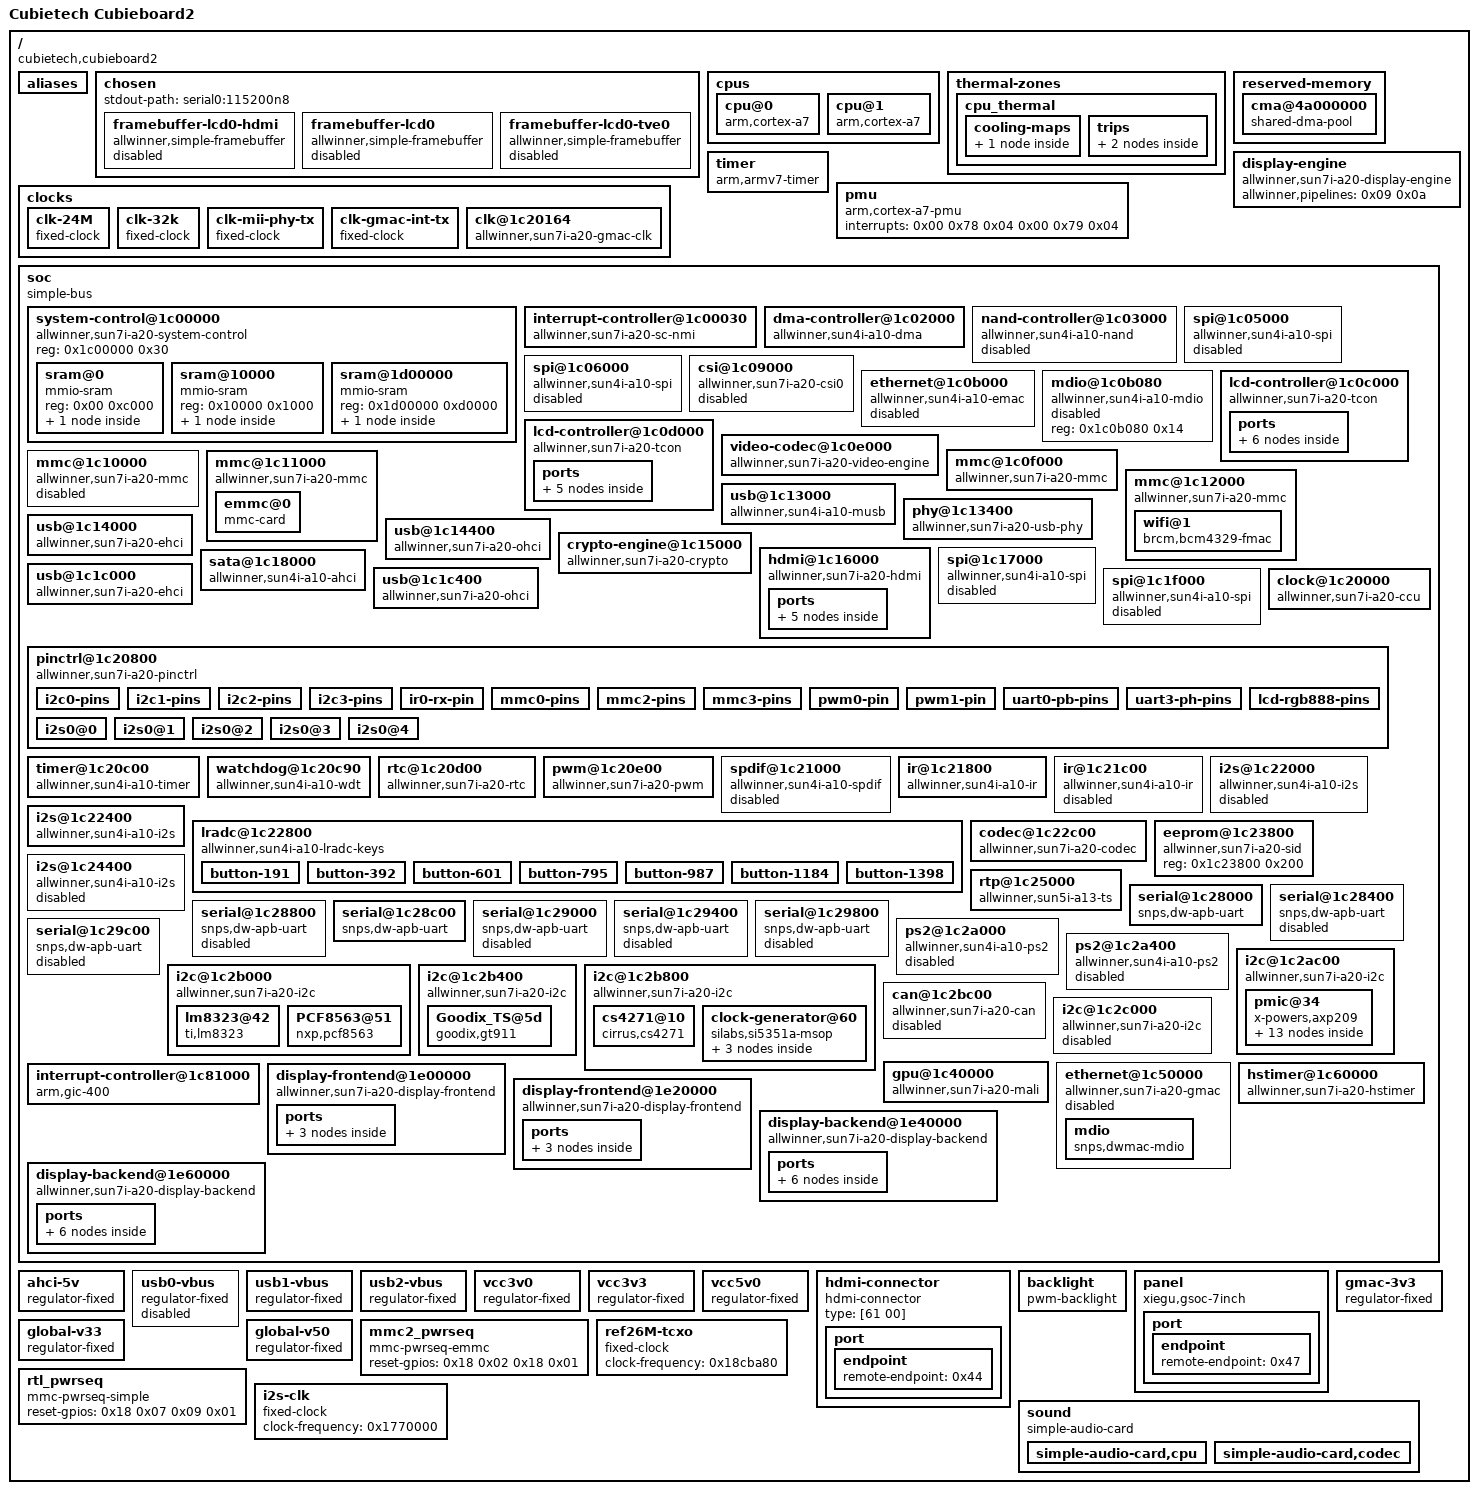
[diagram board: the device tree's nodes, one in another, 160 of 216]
/dts-v1/;

/ {
	interrupt-parent = <0x01>;
	#address-cells = <0x01>;
	#size-cells = <0x01>;
	model = "Cubietech Cubieboard2";
	compatible = "cubietech,cubieboard2\0allwinner,sun7i-a20";

	aliases {
		ethernet0 = "/soc/ethernet@1c50000";
		serial0 = "/soc/serial@1c28000";
	};

	chosen {
		#address-cells = <0x01>;
		#size-cells = <0x01>;
		ranges;
		stdout-path = "serial0:115200n8";

		framebuffer-lcd0-hdmi {
			compatible = "allwinner,simple-framebuffer\0simple-framebuffer";
			allwinner,pipeline = "de_be0-lcd0-hdmi";
			clocks = <0x02 0x38 0x02 0x3c 0x02 0x3e 0x02 0x90 0x02 0x9b 0x02 0x8c 0x02 0xa4>;
			status = "disabled";
		};

		framebuffer-lcd0 {
			compatible = "allwinner,simple-framebuffer\0simple-framebuffer";
			allwinner,pipeline = "de_be0-lcd0";
			clocks = <0x02 0x38 0x02 0x3e 0x02 0x90 0x02 0x95 0x02 0x8c>;
			status = "disabled";
		};

		framebuffer-lcd0-tve0 {
			compatible = "allwinner,simple-framebuffer\0simple-framebuffer";
			allwinner,pipeline = "de_be0-lcd0-tve0";
			clocks = <0x02 0x36 0x02 0x38 0x02 0x3e 0x02 0x90 0x02 0x9b 0x02 0x87 0x02 0x8c>;
			status = "disabled";
		};
	};

	cpus {
		#address-cells = <0x01>;
		#size-cells = <0x00>;

		cpu@0 {
			compatible = "arm,cortex-a7";
			device_type = "cpu";
			reg = <0x00>;
			clocks = <0x02 0x14>;
			clock-latency = <0x3b9b0>;
			operating-points = <0xea600 0x155cc0 0xdea80 0x155cc0 0xd2f00 0x13d620 0xafc80 0x124f80 0x80e80 0x10c8e0 0x4c2c0 0xf4240 0x23280 0xf4240>;
			#cooling-cells = <0x02>;
			phandle = <0x05>;
		};

		cpu@1 {
			compatible = "arm,cortex-a7";
			device_type = "cpu";
			reg = <0x01>;
			clocks = <0x02 0x14>;
			clock-latency = <0x3b9b0>;
			operating-points = <0xea600 0x155cc0 0xdea80 0x155cc0 0xd2f00 0x13d620 0xafc80 0x124f80 0x80e80 0x10c8e0 0x4c2c0 0xf4240 0x23280 0xf4240>;
			#cooling-cells = <0x02>;
			phandle = <0x06>;
		};
	};

	thermal-zones {

		cpu_thermal {
			polling-delay-passive = <0xfa>;
			polling-delay = <0x3e8>;
			thermal-sensors = <0x03>;

			cooling-maps {

				map0 {
					trip = <0x04>;
					cooling-device = <0x05 0xffffffff 0xffffffff 0x06 0xffffffff 0xffffffff>;
				};
			};

			trips {

				cpu_alert0 {
					temperature = <0x124f8>;
					hysteresis = <0x7d0>;
					type = "passive";
					phandle = <0x04>;
				};

				cpu_crit {
					temperature = <0x186a0>;
					hysteresis = <0x7d0>;
					type = "critical";
				};
			};
		};
	};

	reserved-memory {
		#address-cells = <0x01>;
		#size-cells = <0x01>;
		ranges;

		cma@4a000000 {
			compatible = "shared-dma-pool";
			size = <0x8000000>;
			alloc-ranges = <0x4a000000 0x8000000>;
			reusable;
			linux,cma-default;
			phandle = <0x36>;
		};
	};

	timer {
		compatible = "arm,armv7-timer";
		interrupts = <0x01 0x0d 0xf08 0x01 0x0e 0xf08 0x01 0x0b 0xf08 0x01 0x0a 0xf08>;
	};

	pmu {
		compatible = "arm,cortex-a7-pmu";
		interrupts = <0x00 0x78 0x04 0x00 0x79 0x04>;
	};

	clocks {
		#address-cells = <0x01>;
		#size-cells = <0x01>;
		ranges;

		clk-24M {
			#clock-cells = <0x00>;
			compatible = "fixed-clock";
			clock-frequency = <0x16e3600>;
			clock-output-names = "osc24M";
			phandle = <0x23>;
		};

		clk-32k {
			#clock-cells = <0x00>;
			compatible = "fixed-clock";
			clock-frequency = <0x8000>;
			clock-output-names = "osc32k";
			phandle = <0x24>;
		};

		clk-mii-phy-tx {
			#clock-cells = <0x00>;
			compatible = "fixed-clock";
			clock-frequency = <0x17d7840>;
			clock-output-names = "mii_phy_tx";
			phandle = <0x07>;
		};

		clk-gmac-int-tx {
			#clock-cells = <0x00>;
			compatible = "fixed-clock";
			clock-frequency = <0x7735940>;
			clock-output-names = "gmac_int_tx";
			phandle = <0x08>;
		};

		clk@1c20164 {
			#clock-cells = <0x00>;
			compatible = "allwinner,sun7i-a20-gmac-clk";
			reg = <0x1c20164 0x04>;
			clocks = <0x07 0x08>;
			clock-output-names = "gmac_tx";
			phandle = <0x37>;
		};
	};

	display-engine {
		compatible = "allwinner,sun7i-a20-display-engine";
		allwinner,pipelines = <0x09 0x0a>;
		status = "okay";
	};

	soc {
		compatible = "simple-bus";
		#address-cells = <0x01>;
		#size-cells = <0x01>;
		ranges;

		system-control@1c00000 {
			compatible = "allwinner,sun7i-a20-system-control\0allwinner,sun4i-a10-system-control";
			reg = <0x1c00000 0x30>;
			#address-cells = <0x01>;
			#size-cells = <0x01>;
			ranges;

			sram@0 {
				compatible = "mmio-sram";
				reg = <0x00 0xc000>;
				#address-cells = <0x01>;
				#size-cells = <0x01>;
				ranges = <0x00 0x00 0xc000>;

				sram-section@8000 {
					compatible = "allwinner,sun7i-a20-sram-a3-a4\0allwinner,sun4i-a10-sram-a3-a4";
					reg = <0x8000 0x4000>;
					status = "disabled";
					phandle = <0x0c>;
				};
			};

			sram@10000 {
				compatible = "mmio-sram";
				reg = <0x10000 0x1000>;
				#address-cells = <0x01>;
				#size-cells = <0x01>;
				ranges = <0x00 0x10000 0x1000>;

				sram-section@0 {
					compatible = "allwinner,sun7i-a20-sram-d\0allwinner,sun4i-a10-sram-d";
					reg = <0x00 0x1000>;
					status = "okay";
					phandle = <0x1d>;
				};
			};

			sram@1d00000 {
				compatible = "mmio-sram";
				reg = <0x1d00000 0xd0000>;
				#address-cells = <0x01>;
				#size-cells = <0x01>;
				ranges = <0x00 0x1d00000 0xd0000>;

				sram-section@0 {
					compatible = "allwinner,sun7i-a20-sram-c1\0allwinner,sun4i-a10-sram-c1";
					reg = <0x00 0x80000>;
					phandle = <0x15>;
				};
			};
		};

		interrupt-controller@1c00030 {
			compatible = "allwinner,sun7i-a20-sc-nmi";
			interrupt-controller;
			#interrupt-cells = <0x02>;
			reg = <0x1c00030 0x0c>;
			interrupts = <0x00 0x00 0x04>;
			phandle = <0x30>;
		};

		dma-controller@1c02000 {
			compatible = "allwinner,sun4i-a10-dma";
			reg = <0x1c02000 0x1000>;
			interrupts = <0x00 0x1b 0x04>;
			clocks = <0x02 0x20>;
			#dma-cells = <0x02>;
			phandle = <0x0b>;
		};

		nand-controller@1c03000 {
			compatible = "allwinner,sun4i-a10-nand";
			reg = <0x1c03000 0x1000>;
			interrupts = <0x00 0x25 0x04>;
			clocks = <0x02 0x27 0x02 0x60>;
			clock-names = "ahb\0mod";
			dmas = <0x0b 0x01 0x03>;
			dma-names = "rxtx";
			status = "disabled";
			#address-cells = <0x01>;
			#size-cells = <0x00>;
		};

		spi@1c05000 {
			compatible = "allwinner,sun4i-a10-spi";
			reg = <0x1c05000 0x1000>;
			interrupts = <0x00 0x0a 0x04>;
			clocks = <0x02 0x2c 0x02 0x70>;
			clock-names = "ahb\0mod";
			dmas = <0x0b 0x01 0x1b 0x0b 0x01 0x1a>;
			dma-names = "rx\0tx";
			status = "disabled";
			#address-cells = <0x01>;
			#size-cells = <0x00>;
			num-cs = <0x04>;
		};

		spi@1c06000 {
			compatible = "allwinner,sun4i-a10-spi";
			reg = <0x1c06000 0x1000>;
			interrupts = <0x00 0x0b 0x04>;
			clocks = <0x02 0x2d 0x02 0x71>;
			clock-names = "ahb\0mod";
			dmas = <0x0b 0x01 0x09 0x0b 0x01 0x08>;
			dma-names = "rx\0tx";
			status = "disabled";
			#address-cells = <0x01>;
			#size-cells = <0x00>;
			num-cs = <0x01>;
		};

		csi@1c09000 {
			compatible = "allwinner,sun7i-a20-csi0";
			reg = <0x1c09000 0x1000>;
			interrupts = <0x00 0x2a 0x04>;
			clocks = <0x02 0x3a 0x02 0x97 0x02 0x83>;
			clock-names = "bus\0isp\0ram";
			resets = <0x02 0x0e>;
			status = "disabled";
		};

		ethernet@1c0b000 {
			compatible = "allwinner,sun4i-a10-emac";
			reg = <0x1c0b000 0x1000>;
			interrupts = <0x00 0x37 0x04>;
			clocks = <0x02 0x2a>;
			allwinner,sram = <0x0c 0x01>;
			status = "disabled";
		};

		mdio@1c0b080 {
			compatible = "allwinner,sun4i-a10-mdio";
			reg = <0x1c0b080 0x14>;
			status = "disabled";
			#address-cells = <0x01>;
			#size-cells = <0x00>;
		};

		lcd-controller@1c0c000 {
			compatible = "allwinner,sun7i-a20-tcon";
			reg = <0x1c0c000 0x1000>;
			interrupts = <0x00 0x2c 0x04>;
			resets = <0x02 0x0b>;
			reset-names = "lcd";
			clocks = <0x02 0x38 0x02 0x95 0x02 0x9b>;
			clock-names = "ahb\0tcon-ch0\0tcon-ch1";
			clock-output-names = "tcon0-pixel-clock";
			#clock-cells = <0x00>;
			dmas = <0x0b 0x01 0x0e>;
			pinctrl-names = "default";
			pinctrl-0 = <0x0d>;
			status = "okay";

			ports {
				#address-cells = <0x01>;
				#size-cells = <0x00>;

				port@0 {
					#address-cells = <0x01>;
					#size-cells = <0x00>;
					reg = <0x00>;

					endpoint@0 {
						reg = <0x00>;
						remote-endpoint = <0x0e>;
						phandle = <0x42>;
					};

					endpoint@1 {
						reg = <0x01>;
						remote-endpoint = <0x0f>;
						phandle = <0x3e>;
					};
				};

				port@1 {
					#address-cells = <0x01>;
					#size-cells = <0x00>;
					reg = <0x01>;

					endpoint@1 {
						reg = <0x01>;
						remote-endpoint = <0x10>;
						allwinner,tcon-channel = <0x01>;
						phandle = <0x1f>;
					};

					endpoint@0 {
						reg = <0x00>;
						remote-endpoint = <0x11>;
						phandle = <0x47>;
					};
				};
			};
		};

		lcd-controller@1c0d000 {
			compatible = "allwinner,sun7i-a20-tcon";
			reg = <0x1c0d000 0x1000>;
			interrupts = <0x00 0x2d 0x04>;
			resets = <0x02 0x0d>;
			reset-names = "lcd";
			clocks = <0x02 0x39 0x02 0x96 0x02 0x9d>;
			clock-names = "ahb\0tcon-ch0\0tcon-ch1";
			clock-output-names = "tcon1-pixel-clock";
			#clock-cells = <0x00>;
			dmas = <0x0b 0x01 0x0f>;

			ports {
				#address-cells = <0x01>;
				#size-cells = <0x00>;

				port@0 {
					#address-cells = <0x01>;
					#size-cells = <0x00>;
					reg = <0x00>;

					endpoint@0 {
						reg = <0x00>;
						remote-endpoint = <0x12>;
						phandle = <0x43>;
					};

					endpoint@1 {
						reg = <0x01>;
						remote-endpoint = <0x13>;
						phandle = <0x3f>;
					};
				};

				port@1 {
					#address-cells = <0x01>;
					#size-cells = <0x00>;
					reg = <0x01>;

					endpoint@1 {
						reg = <0x01>;
						remote-endpoint = <0x14>;
						allwinner,tcon-channel = <0x01>;
						phandle = <0x20>;
					};
				};
			};
		};

		video-codec@1c0e000 {
			compatible = "allwinner,sun7i-a20-video-engine";
			reg = <0x1c0e000 0x1000>;
			clocks = <0x02 0x34 0x02 0xa1 0x02 0x82>;
			clock-names = "ahb\0mod\0ram";
			resets = <0x02 0x10>;
			interrupts = <0x00 0x35 0x04>;
			allwinner,sram = <0x15 0x01>;
		};

		mmc@1c0f000 {
			compatible = "allwinner,sun7i-a20-mmc";
			reg = <0x1c0f000 0x1000>;
			clocks = <0x02 0x22 0x02 0x62 0x02 0x63 0x02 0x64>;
			clock-names = "ahb\0mmc\0output\0sample";
			interrupts = <0x00 0x20 0x04>;
			pinctrl-names = "default";
			pinctrl-0 = <0x16>;
			status = "okay";
			#address-cells = <0x01>;
			#size-cells = <0x00>;
			vmmc-supply = <0x17>;
			bus-width = <0x04>;
			cd-gpios = <0x18 0x04 0x00 0x01>;
		};

		mmc@1c10000 {
			compatible = "allwinner,sun7i-a20-mmc";
			reg = <0x1c10000 0x1000>;
			clocks = <0x02 0x23 0x02 0x65 0x02 0x66 0x02 0x67>;
			clock-names = "ahb\0mmc\0output\0sample";
			interrupts = <0x00 0x21 0x04>;
			status = "disabled";
			#address-cells = <0x01>;
			#size-cells = <0x00>;
		};

		mmc@1c11000 {
			compatible = "allwinner,sun7i-a20-mmc";
			reg = <0x1c11000 0x1000>;
			clocks = <0x02 0x24 0x02 0x68 0x02 0x69 0x02 0x6a>;
			clock-names = "ahb\0mmc\0output\0sample";
			interrupts = <0x00 0x22 0x04>;
			pinctrl-names = "default";
			pinctrl-0 = <0x19>;
			status = "okay";
			#address-cells = <0x01>;
			#size-cells = <0x00>;
			vmmc-supply = <0x17>;
			mmc-pwrseq = <0x1a>;
			reset-gpios = <0x18 0x02 0x18 0x01>;
			bus-width = <0x04>;
			non-removable;

			emmc@0 {
				reg = <0x00>;
				compatible = "mmc-card";
				broken-hpi;
			};
		};

		mmc@1c12000 {
			compatible = "allwinner,sun7i-a20-mmc";
			reg = <0x1c12000 0x1000>;
			clocks = <0x02 0x25 0x02 0x6b 0x02 0x6c 0x02 0x6d>;
			clock-names = "ahb\0mmc\0output\0sample";
			interrupts = <0x00 0x23 0x04>;
			pinctrl-names = "default";
			pinctrl-0 = <0x1b>;
			status = "okay";
			#address-cells = <0x01>;
			#size-cells = <0x00>;
			vmmc-supply = <0x17>;
			bus-width = <0x04>;
			non-removable;

			wifi@1 {
				reg = <0x01>;
				compatible = "brcm,bcm4329-fmac";
				interrupt-parent = <0x18>;
				interrupts = <0x07 0x0a 0x08>;
				interrupt-names = "host-wake";
			};
		};

		usb@1c13000 {
			compatible = "allwinner,sun4i-a10-musb";
			reg = <0x1c13000 0x400>;
			clocks = <0x02 0x1a>;
			interrupts = <0x00 0x26 0x04>;
			interrupt-names = "mc";
			phys = <0x1c 0x00>;
			phy-names = "usb";
			extcon = <0x1c 0x00>;
			allwinner,sram = <0x1d 0x01>;
			dr_mode = "otg";
			status = "okay";
		};

		phy@1c13400 {
			#phy-cells = <0x01>;
			compatible = "allwinner,sun7i-a20-usb-phy";
			reg = <0x1c13400 0x10 0x1c14800 0x04 0x1c1c800 0x04>;
			reg-names = "phy_ctrl\0pmu1\0pmu2";
			clocks = <0x02 0x7d>;
			clock-names = "usb_phy";
			resets = <0x02 0x01 0x02 0x02 0x02 0x03>;
			reset-names = "usb0_reset\0usb1_reset\0usb2_reset";
			status = "okay";
			usb0_id_det-gpios = <0x18 0x07 0x04 0x10>;
			usb0_vbus_det-gpios = <0x18 0x07 0x11 0x20>;
			usb0_vbus-supply = <0x1e>;
			usb1_vbus-supply = <0x1e>;
			usb2_vbus-supply = <0x1e>;
			phandle = <0x1c>;
		};

		usb@1c14000 {
			compatible = "allwinner,sun7i-a20-ehci\0generic-ehci";
			reg = <0x1c14000 0x100>;
			interrupts = <0x00 0x27 0x04>;
			clocks = <0x02 0x1b>;
			phys = <0x1c 0x01>;
			phy-names = "usb";
			status = "okay";
		};

		usb@1c14400 {
			compatible = "allwinner,sun7i-a20-ohci\0generic-ohci";
			reg = <0x1c14400 0x100>;
			interrupts = <0x00 0x40 0x04>;
			clocks = <0x02 0x7b 0x02 0x1c>;
			phys = <0x1c 0x01>;
			phy-names = "usb";
			status = "okay";
		};

		crypto-engine@1c15000 {
			compatible = "allwinner,sun7i-a20-crypto\0allwinner,sun4i-a10-crypto";
			reg = <0x1c15000 0x1000>;
			interrupts = <0x00 0x56 0x04>;
			clocks = <0x02 0x1f 0x02 0x6f>;
			clock-names = "ahb\0mod";
		};

		hdmi@1c16000 {
			compatible = "allwinner,sun7i-a20-hdmi\0allwinner,sun5i-a10s-hdmi";
			reg = <0x1c16000 0x1000>;
			interrupts = <0x00 0x3a 0x04>;
			clocks = <0x02 0x3c 0x02 0xa4 0x02 0x09 0x02 0x12>;
			clock-names = "ahb\0mod\0pll-0\0pll-1";
			dmas = <0x0b 0x00 0x10 0x0b 0x00 0x10 0x0b 0x01 0x18>;
			dma-names = "ddc-tx\0ddc-rx\0audio-tx";
			status = "okay";

			ports {
				#address-cells = <0x01>;
				#size-cells = <0x00>;

				port@0 {
					#address-cells = <0x01>;
					#size-cells = <0x00>;
					reg = <0x00>;

					endpoint@0 {
						reg = <0x00>;
						remote-endpoint = <0x1f>;
						phandle = <0x10>;
					};

					endpoint@1 {
						reg = <0x01>;
						remote-endpoint = <0x20>;
						phandle = <0x14>;
					};
				};

				port@1 {
					reg = <0x01>;

					endpoint {
						remote-endpoint = <0x21>;
						phandle = <0x44>;
					};
				};
			};
		};

		spi@1c17000 {
			compatible = "allwinner,sun4i-a10-spi";
			reg = <0x1c17000 0x1000>;
			interrupts = <0x00 0x0c 0x04>;
			clocks = <0x02 0x2e 0x02 0x72>;
			clock-names = "ahb\0mod";
			dmas = <0x0b 0x01 0x1d 0x0b 0x01 0x1c>;
			dma-names = "rx\0tx";
			status = "disabled";
			#address-cells = <0x01>;
			#size-cells = <0x00>;
			num-cs = <0x01>;
		};

		sata@1c18000 {
			compatible = "allwinner,sun4i-a10-ahci";
			reg = <0x1c18000 0x1000>;
			interrupts = <0x00 0x38 0x04>;
			clocks = <0x02 0x31 0x02 0x7a>;
			status = "okay";
			target-supply = <0x22>;
		};

		usb@1c1c000 {
			compatible = "allwinner,sun7i-a20-ehci\0generic-ehci";
			reg = <0x1c1c000 0x100>;
			interrupts = <0x00 0x28 0x04>;
			clocks = <0x02 0x1d>;
			phys = <0x1c 0x02>;
			phy-names = "usb";
			status = "okay";
		};

		usb@1c1c400 {
			compatible = "allwinner,sun7i-a20-ohci\0generic-ohci";
			reg = <0x1c1c400 0x100>;
			interrupts = <0x00 0x41 0x04>;
			clocks = <0x02 0x7c 0x02 0x1e>;
			phys = <0x1c 0x02>;
			phy-names = "usb";
			status = "okay";
		};

		spi@1c1f000 {
			compatible = "allwinner,sun4i-a10-spi";
			reg = <0x1c1f000 0x1000>;
			interrupts = <0x00 0x32 0x04>;
			clocks = <0x02 0x2f 0x02 0x7f>;
			clock-names = "ahb\0mod";
			dmas = <0x0b 0x01 0x1f 0x0b 0x01 0x1e>;
			dma-names = "rx\0tx";
			status = "disabled";
			#address-cells = <0x01>;
			#size-cells = <0x00>;
			num-cs = <0x01>;
		};

		clock@1c20000 {
			compatible = "allwinner,sun7i-a20-ccu";
			reg = <0x1c20000 0x400>;
			clocks = <0x23 0x24>;
			clock-names = "hosc\0losc";
			#clock-cells = <0x01>;
			#reset-cells = <0x01>;
			phandle = <0x02>;
		};

		pinctrl@1c20800 {
			compatible = "allwinner,sun7i-a20-pinctrl";
			reg = <0x1c20800 0x400>;
			interrupts = <0x00 0x1c 0x04>;
			clocks = <0x02 0x4a 0x23 0x24>;
			clock-names = "apb\0hosc\0losc";
			gpio-controller;
			interrupt-controller;
			#interrupt-cells = <0x03>;
			#gpio-cells = <0x03>;
			phandle = <0x18>;

			i2c0-pins {
				pins = "PB0\0PB1";
				function = "i2c0";
				phandle = <0x2f>;
			};

			i2c1-pins {
				pins = "PB18\0PB19";
				function = "i2c1";
				phandle = <0x31>;
			};

			i2c2-pins {
				pins = "PB20\0PB21";
				function = "i2c2";
				phandle = <0x32>;
			};

			i2c3-pins {
				pins = "PI0\0PI1";
				function = "i2c3";
				phandle = <0x33>;
			};

			ir0-rx-pin {
				pins = "PB4";
				function = "ir0";
				phandle = <0x27>;
			};

			mmc0-pins {
				pins = "PF0\0PF1\0PF2\0PF3\0PF4\0PF5";
				function = "mmc0";
				drive-strength = <0x1e>;
				bias-pull-up;
				phandle = <0x16>;
			};

			mmc2-pins {
				pins = "PC6\0PC7\0PC8\0PC9\0PC10\0PC11";
				function = "mmc2";
				drive-strength = <0x1e>;
				bias-pull-up;
				phandle = <0x19>;
			};

			mmc3-pins {
				pins = "PI4\0PI5\0PI6\0PI7\0PI8\0PI9";
				function = "mmc3";
				drive-strength = <0x1e>;
				bias-pull-up;
				phandle = <0x1b>;
			};

			pwm0-pin {
				pins = "PB2";
				function = "pwm";
				phandle = <0x25>;
			};

			pwm1-pin {
				pins = "PI3";
				function = "pwm";
				phandle = <0x26>;
			};

			uart0-pb-pins {
				pins = "PB22\0PB23";
				function = "uart0";
				phandle = <0x2d>;
			};

			uart3-ph-pins {
				pins = "PH0\0PH1";
				function = "uart3";
				phandle = <0x2e>;
			};

			lcd-rgb888-pins {
				pins = "PD0\0PD1\0PD2\0PD3\0PD4\0PD5\0PD6\0PD7\0PD8\0PD9\0PD10\0PD11\0PD12\0PD13\0PD14\0PD15\0PD16\0PD17\0PD18\0PD19\0PD20\0PD21\0PD22\0PD23\0PD24\0PD25\0PD26\0PD27";
				function = "lcd0";
				phandle = <0x0d>;
			};

			i2s0@0 {
				allwinner,pins = "PB5";
				allwinner,function = "i2s0";
			};

			i2s0@1 {
				allwinner,pins = "PB6";
				allwinner,function = "i2s0";
				phandle = <0x28>;
			};

			i2s0@2 {
				allwinner,pins = "PB7";
				allwinner,function = "i2s0";
				phandle = <0x29>;
			};

			i2s0@3 {
				allwinner,pins = "PB8";
				allwinner,function = "i2s0";
				phandle = <0x2a>;
			};

			i2s0@4 {
				allwinner,pins = "PB12";
				allwinner,function = "i2s0";
				phandle = <0x2b>;
			};
		};

		timer@1c20c00 {
			compatible = "allwinner,sun4i-a10-timer";
			reg = <0x1c20c00 0x90>;
			interrupts = <0x00 0x16 0x04 0x00 0x17 0x04 0x00 0x18 0x04 0x00 0x19 0x04 0x00 0x43 0x04 0x00 0x44 0x04>;
			clocks = <0x23>;
		};

		watchdog@1c20c90 {
			compatible = "allwinner,sun4i-a10-wdt";
			reg = <0x1c20c90 0x10>;
			interrupts = <0x00 0x18 0x04>;
			clocks = <0x23>;
		};

		rtc@1c20d00 {
			compatible = "allwinner,sun7i-a20-rtc";
			reg = <0x1c20d00 0x20>;
			interrupts = <0x00 0x18 0x04>;
		};

		pwm@1c20e00 {
			compatible = "allwinner,sun7i-a20-pwm";
			reg = <0x1c20e00 0x0c>;
			clocks = <0x23>;
			#pwm-cells = <0x03>;
			status = "okay";
			pinctrl-names = "default";
			pinctrl-0 = <0x25 0x26>;
			phandle = <0x45>;
		};

		spdif@1c21000 {
			#sound-dai-cells = <0x00>;
			compatible = "allwinner,sun4i-a10-spdif";
			reg = <0x1c21000 0x400>;
			interrupts = <0x00 0x0d 0x04>;
			clocks = <0x02 0x46 0x02 0x78>;
			clock-names = "apb\0spdif";
			dmas = <0x0b 0x00 0x02 0x0b 0x00 0x02>;
			dma-names = "rx\0tx";
			status = "disabled";
		};

		ir@1c21800 {
			compatible = "allwinner,sun4i-a10-ir";
			clocks = <0x02 0x4b 0x02 0x74>;
			clock-names = "apb\0ir";
			interrupts = <0x00 0x05 0x04>;
			reg = <0x1c21800 0x40>;
			status = "okay";
			pinctrl-names = "default";
			pinctrl-0 = <0x27>;
		};

		ir@1c21c00 {
			compatible = "allwinner,sun4i-a10-ir";
			clocks = <0x02 0x4c 0x02 0x75>;
			clock-names = "apb\0ir";
			interrupts = <0x00 0x06 0x04>;
			reg = <0x1c21c00 0x40>;
			status = "disabled";
		};

		i2s@1c22000 {
			#sound-dai-cells = <0x00>;
			compatible = "allwinner,sun4i-a10-i2s";
			reg = <0x1c22000 0x400>;
			interrupts = <0x00 0x57 0x04>;
			clocks = <0x02 0x49 0x02 0x80>;
			clock-names = "apb\0mod";
			dmas = <0x0b 0x00 0x04 0x0b 0x00 0x04>;
			dma-names = "rx\0tx";
			status = "disabled";
		};

		i2s@1c22400 {
			#sound-dai-cells = <0x00>;
			compatible = "allwinner,sun4i-a10-i2s";
			reg = <0x1c22400 0x400>;
			interrupts = <0x00 0x10 0x04>;
			clocks = <0x02 0x47 0x02 0x76>;
			clock-names = "apb\0mod";
			dmas = <0x0b 0x00 0x03 0x0b 0x00 0x03>;
			dma-names = "rx\0tx";
			status = "okay";
			pinctrl-names = "default";
			pinctrl-0 = <0x28 0x29 0x2a 0x2b>;
			phandle = <0x49>;
		};

		lradc@1c22800 {
			compatible = "allwinner,sun4i-a10-lradc-keys";
			reg = <0x1c22800 0x100>;
			interrupts = <0x00 0x1f 0x04>;
			status = "okay";
			vref-supply = <0x2c>;

			button-191 {
				label = "Volume Up";
				linux,code = <0x73>;
				channel = <0x00>;
				voltage = <0x2eb2a>;
			};

			button-392 {
				label = "Volume Down";
				linux,code = <0x72>;
				channel = <0x00>;
				voltage = <0x5fdc4>;
			};

			button-601 {
				label = "Menu";
				linux,code = <0x8b>;
				channel = <0x00>;
				voltage = <0x92c3f>;
			};

			button-795 {
				label = "Search";
				linux,code = <0xd9>;
				channel = <0x00>;
				voltage = <0xc21d2>;
			};

			button-987 {
				label = "Home";
				linux,code = <0xac>;
				channel = <0x00>;
				voltage = <0xf10fb>;
			};

			button-1184 {
				label = "Esc";
				linux,code = <0x01>;
				channel = <0x00>;
				voltage = <0x1213a6>;
			};

			button-1398 {
				label = "Enter";
				linux,code = <0x1c>;
				channel = <0x00>;
				voltage = <0x155814>;
			};
		};

		codec@1c22c00 {
			#sound-dai-cells = <0x00>;
			compatible = "allwinner,sun7i-a20-codec";
			reg = <0x1c22c00 0x40>;
			interrupts = <0x00 0x1e 0x04>;
			clocks = <0x02 0x45 0x02 0xa0>;
			clock-names = "apb\0codec";
			dmas = <0x0b 0x00 0x13 0x0b 0x00 0x13>;
			dma-names = "rx\0tx";
			status = "okay";
			allwinner,audio-routing = "Headphone\0HP\0Speaker\0LINEOUT\0LINEIN\0Line In\0MIC1\0HBIAS\0MIC1\0Mic1\0MIC2\0HBIAS\0MIC2\0Mic2";
		};

		eeprom@1c23800 {
			compatible = "allwinner,sun7i-a20-sid";
			reg = <0x1c23800 0x200>;
		};

		i2s@1c24400 {
			#sound-dai-cells = <0x00>;
			compatible = "allwinner,sun4i-a10-i2s";
			reg = <0x1c24400 0x400>;
			interrupts = <0x00 0x5a 0x04>;
			clocks = <0x02 0x4d 0x02 0x81>;
			clock-names = "apb\0mod";
			dmas = <0x0b 0x00 0x06 0x0b 0x00 0x06>;
			dma-names = "rx\0tx";
			status = "disabled";
		};

		rtp@1c25000 {
			compatible = "allwinner,sun5i-a13-ts";
			reg = <0x1c25000 0x100>;
			interrupts = <0x00 0x1d 0x04>;
			#thermal-sensor-cells = <0x00>;
			phandle = <0x03>;
		};

		serial@1c28000 {
			compatible = "snps,dw-apb-uart";
			reg = <0x1c28000 0x400>;
			interrupts = <0x00 0x01 0x04>;
			reg-shift = <0x02>;
			reg-io-width = <0x04>;
			clocks = <0x02 0x58>;
			status = "okay";
			pinctrl-names = "default";
			pinctrl-0 = <0x2d>;
		};

		serial@1c28400 {
			compatible = "snps,dw-apb-uart";
			reg = <0x1c28400 0x400>;
			interrupts = <0x00 0x02 0x04>;
			reg-shift = <0x02>;
			reg-io-width = <0x04>;
			clocks = <0x02 0x59>;
			status = "disabled";
		};

		serial@1c28800 {
			compatible = "snps,dw-apb-uart";
			reg = <0x1c28800 0x400>;
			interrupts = <0x00 0x03 0x04>;
			reg-shift = <0x02>;
			reg-io-width = <0x04>;
			clocks = <0x02 0x5a>;
			status = "disabled";
		};

		serial@1c28c00 {
			compatible = "snps,dw-apb-uart";
			reg = <0x1c28c00 0x400>;
			interrupts = <0x00 0x04 0x04>;
			reg-shift = <0x02>;
			reg-io-width = <0x04>;
			clocks = <0x02 0x5b>;
			status = "okay";
			pinctrl-names = "default";
			pinctrl-0 = <0x2e>;
		};

		serial@1c29000 {
			compatible = "snps,dw-apb-uart";
			reg = <0x1c29000 0x400>;
			interrupts = <0x00 0x11 0x04>;
			reg-shift = <0x02>;
			reg-io-width = <0x04>;
			clocks = <0x02 0x5c>;
			status = "disabled";
		};

		serial@1c29400 {
			compatible = "snps,dw-apb-uart";
			reg = <0x1c29400 0x400>;
			interrupts = <0x00 0x12 0x04>;
			reg-shift = <0x02>;
			reg-io-width = <0x04>;
			clocks = <0x02 0x5d>;
			status = "disabled";
		};

		serial@1c29800 {
			compatible = "snps,dw-apb-uart";
			reg = <0x1c29800 0x400>;
			interrupts = <0x00 0x13 0x04>;
			reg-shift = <0x02>;
			reg-io-width = <0x04>;
			clocks = <0x02 0x5e>;
			status = "disabled";
		};

		serial@1c29c00 {
			compatible = "snps,dw-apb-uart";
			reg = <0x1c29c00 0x400>;
			interrupts = <0x00 0x14 0x04>;
			reg-shift = <0x02>;
			reg-io-width = <0x04>;
			clocks = <0x02 0x5f>;
			status = "disabled";
		};

		ps2@1c2a000 {
			compatible = "allwinner,sun4i-a10-ps2";
			reg = <0x1c2a000 0x400>;
			interrupts = <0x00 0x3e 0x04>;
			clocks = <0x02 0x55>;
			status = "disabled";
		};

		ps2@1c2a400 {
			compatible = "allwinner,sun4i-a10-ps2";
			reg = <0x1c2a400 0x400>;
			interrupts = <0x00 0x3f 0x04>;
			clocks = <0x02 0x56>;
			status = "disabled";
		};

		i2c@1c2ac00 {
			compatible = "allwinner,sun7i-a20-i2c\0allwinner,sun4i-a10-i2c";
			reg = <0x1c2ac00 0x400>;
			interrupts = <0x00 0x07 0x04>;
			clocks = <0x02 0x4f>;
			pinctrl-names = "default";
			pinctrl-0 = <0x2f>;
			status = "okay";
			#address-cells = <0x01>;
			#size-cells = <0x00>;

			pmic@34 {
				reg = <0x34>;
				interrupt-parent = <0x30>;
				interrupts = <0x00 0x08>;
				compatible = "x-powers,axp209";
				interrupt-controller;
				#interrupt-cells = <0x01>;

				ac-power-supply {
					compatible = "x-powers,axp202-ac-power-supply";
					status = "okay";
				};

				adc {
					compatible = "x-powers,axp209-adc";
					#io-channel-cells = <0x01>;
				};

				gpio {
					compatible = "x-powers,axp209-gpio";
					gpio-controller;
					#gpio-cells = <0x02>;
				};

				battery-power-supply {
					compatible = "x-powers,axp209-battery-power-supply";
					status = "disabled";
				};

				regulators {
					x-powers,dcdc-freq = <0x5dc>;

					dcdc2 {
						regulator-name = "vdd-cpu";
						regulator-always-on;
						regulator-min-microvolt = <0xf4240>;
						regulator-max-microvolt = <0x162010>;
					};

					dcdc3 {
						regulator-name = "vdd-int-dll";
						regulator-always-on;
						regulator-min-microvolt = <0xf4240>;
						regulator-max-microvolt = <0x155cc0>;
					};

					ldo1 {
						regulator-always-on;
						regulator-min-microvolt = <0x13d620>;
						regulator-max-microvolt = <0x13d620>;
						regulator-name = "vdd-rtc";
					};

					ldo2 {
						regulator-name = "avcc";
						regulator-always-on;
						regulator-min-microvolt = <0x2dc6c0>;
						regulator-max-microvolt = <0x2dc6c0>;
					};

					ldo3 {
						regulator-name = "csi0-io";
						regulator-always-on;
						regulator-min-microvolt = <0x2ab980>;
						regulator-max-microvolt = <0x2ab980>;
					};

					ldo4 {
						regulator-name = "ldo4";
					};

					ldo5 {
						regulator-name = "ldo5";
						status = "disabled";
					};
				};

				usb-power-supply {
					compatible = "x-powers,axp202-usb-power-supply";
					status = "disabled";
				};
			};
		};

		i2c@1c2b000 {
			compatible = "allwinner,sun7i-a20-i2c\0allwinner,sun4i-a10-i2c";
			reg = <0x1c2b000 0x400>;
			interrupts = <0x00 0x08 0x04>;
			clocks = <0x02 0x50>;
			pinctrl-names = "default";
			pinctrl-0 = <0x31>;
			status = "okay";
			#address-cells = <0x01>;
			#size-cells = <0x00>;

			lm8323@42 {
				compatible = "ti,lm8323";
				reg = <0x42>;
				interrupt-parent = <0x18>;
				interrupts = <0x07 0x03 0x02>;
				interrupt-names = "irq";
				irq-gpios = <0x18 0x07 0x03 0x00>;
				size_x = <0x04>;
				size_y = <0x04>;
				debounce_time = <0x02>;
				active_time = <0x3e8>;
			};

			PCF8563@51 {
				compatible = "nxp,pcf8563";
				reg = <0x51>;
				interrupt-parent = <0x18>;
				interrupts = <0x07 0x06 0x02>;
				interrupt-names = "irq";
				irq-gpios = <0x18 0x07 0x06 0x00>;
			};
		};

		i2c@1c2b400 {
			compatible = "allwinner,sun7i-a20-i2c\0allwinner,sun4i-a10-i2c";
			reg = <0x1c2b400 0x400>;
			interrupts = <0x00 0x09 0x04>;
			clocks = <0x02 0x51>;
			pinctrl-names = "default";
			pinctrl-0 = <0x32>;
			status = "okay";
			#address-cells = <0x01>;
			#size-cells = <0x00>;

			Goodix_TS@5d {
				compatible = "goodix,gt911";
				reg = <0x5d>;
				interrupt-parent = <0x18>;
				interrupts = <0x07 0x02 0x02>;
				interrupt-names = "irq";
				irq-gpios = <0x18 0x07 0x02 0x00>;
				reset-gpios = <0x18 0x07 0x19 0x00>;
				gt911,cfg-data = [00 00 04 58 02 05 3d 20 01 08 28 05 50 32 03 05 00 00 00 00 00 00 05 17 19 1c 14 87 29 0a 19 1b d6 07 00 00 00 01 03 10 00 01 00 00 00 03 64 32 00 00 00 0f 2d 94 c5 02 07 00 00 04 c0 10 00 9c 14 00 7b 1a 00 66 20 00 54 28 00 54 00 00 00 00 00 00 00 00 00 00 00 00 00 00 00 00 00 00 00 00 00 00 00 00 00 00 00 00 00 00 00 00 00 00 00 00 02 04 06 08 0a 0c 0e 10 12 14 ff ff ff ff ff ff ff ff ff ff ff ff ff ff ff ff ff ff ff ff 00 02 04 06 08 0a 0c 1d 1e 1f 20 21 22 24 26 28 ff ff ff ff ff ff ff ff ff ff ff ff ff ff ff ff ff ff ff ff ff ff ff ff ff ff bb 01];
			};
		};

		i2c@1c2b800 {
			compatible = "allwinner,sun7i-a20-i2c\0allwinner,sun4i-a10-i2c";
			reg = <0x1c2b800 0x400>;
			interrupts = <0x00 0x58 0x04>;
			clocks = <0x02 0x52>;
			pinctrl-names = "default";
			pinctrl-0 = <0x33>;
			status = "okay";
			#address-cells = <0x01>;
			#size-cells = <0x00>;

			cs4271@10 {
				#sound-dai-cells = <0x00>;
				compatible = "cirrus,cs4271";
				reg = <0x10>;
				reset-gpio = <0x18 0x08 0x02 0x01>;
				vl-supply = <0x34>;
				vd-supply = <0x34>;
				va-supply = <0x1e>;
				enable-soft-reset = <0x01>;
				amutec-eq-bmutec = <0x00>;
				status = "okay";
				phandle = <0x4b>;
			};

			clock-generator@60 {
				compatible = "silabs,si5351a-msop";
				reg = <0x60>;
				#address-cells = <0x01>;
				#size-cells = <0x00>;
				#clock-cells = <0x01>;
				clocks = <0x35>;
				clock-names = "xtal";
				silabs,pll-source = <0x00 0x00 0x01 0x00>;

				clkout0 {
					reg = <0x00>;
					silabs,drive-strength = <0x02>;
					silabs,multisynth-source = <0x00>;
					silabs,clock-source = <0x00>;
					silabs,pll-master;
					clock-frequency = <0x8661ce8>;
				};

				clkout1 {
					reg = <0x01>;
					silabs,clock-source = <0x01>;
				};

				clkout2 {
					reg = <0x02>;
					silabs,drive-strength = <0x02>;
					silabs,multisynth-source = <0x01>;
					silabs,clock-source = <0x00>;
					silabs,pll-master;
					clock-frequency = <0x186a000>;
				};
			};
		};

		can@1c2bc00 {
			compatible = "allwinner,sun7i-a20-can\0allwinner,sun4i-a10-can";
			reg = <0x1c2bc00 0x400>;
			interrupts = <0x00 0x1a 0x04>;
			clocks = <0x02 0x53>;
			status = "disabled";
		};

		i2c@1c2c000 {
			compatible = "allwinner,sun7i-a20-i2c\0allwinner,sun4i-a10-i2c";
			reg = <0x1c2c000 0x400>;
			interrupts = <0x00 0x59 0x04>;
			clocks = <0x02 0x57>;
			status = "disabled";
			#address-cells = <0x01>;
			#size-cells = <0x00>;
		};

		gpu@1c40000 {
			compatible = "allwinner,sun7i-a20-mali\0arm,mali-400";
			reg = <0x1c40000 0x10000>;
			interrupts = <0x00 0x45 0x04 0x00 0x46 0x04 0x00 0x47 0x04 0x00 0x48 0x04 0x00 0x4a 0x04 0x00 0x4b 0x04 0x00 0x49 0x04>;
			interrupt-names = "gp\0gpmmu\0pp0\0ppmmu0\0pp1\0ppmmu1\0pmu";
			clocks = <0x02 0x44 0x02 0xa5>;
			clock-names = "bus\0core";
			resets = <0x02 0x13>;
			memory-region = <0x36>;
			assigned-clocks = <0x02 0xa5>;
			assigned-clock-rates = <0x16e36000>;
			status = "okay";
		};

		ethernet@1c50000 {
			compatible = "allwinner,sun7i-a20-gmac";
			reg = <0x1c50000 0x10000>;
			interrupts = <0x00 0x55 0x04>;
			interrupt-names = "macirq";
			clocks = <0x02 0x42 0x37>;
			clock-names = "stmmaceth\0allwinner_gmac_tx";
			snps,pbl = <0x02>;
			snps,fixed-burst;
			snps,force_sf_dma_mode;
			status = "disabled";

			mdio {
				compatible = "snps,dwmac-mdio";
				#address-cells = <0x01>;
				#size-cells = <0x00>;
			};
		};

		hstimer@1c60000 {
			compatible = "allwinner,sun7i-a20-hstimer";
			reg = <0x1c60000 0x1000>;
			interrupts = <0x00 0x51 0x04 0x00 0x52 0x04 0x00 0x53 0x04 0x00 0x54 0x04>;
			clocks = <0x02 0x33>;
		};

		interrupt-controller@1c81000 {
			compatible = "arm,gic-400";
			reg = <0x1c81000 0x1000 0x1c82000 0x2000 0x1c84000 0x2000 0x1c86000 0x2000>;
			interrupt-controller;
			#interrupt-cells = <0x03>;
			interrupts = <0x01 0x09 0xf04>;
			phandle = <0x01>;
		};

		display-frontend@1e00000 {
			compatible = "allwinner,sun7i-a20-display-frontend";
			reg = <0x1e00000 0x20000>;
			interrupts = <0x00 0x2f 0x04>;
			clocks = <0x02 0x40 0x02 0x92 0x02 0x8b>;
			clock-names = "ahb\0mod\0ram";
			resets = <0x02 0x07>;
			phandle = <0x09>;

			ports {
				#address-cells = <0x01>;
				#size-cells = <0x00>;

				port@1 {
					#address-cells = <0x01>;
					#size-cells = <0x00>;
					reg = <0x01>;

					endpoint@0 {
						reg = <0x00>;
						remote-endpoint = <0x38>;
						phandle = <0x40>;
					};

					endpoint@1 {
						reg = <0x01>;
						remote-endpoint = <0x39>;
						phandle = <0x3c>;
					};
				};
			};
		};

		display-frontend@1e20000 {
			compatible = "allwinner,sun7i-a20-display-frontend";
			reg = <0x1e20000 0x20000>;
			interrupts = <0x00 0x30 0x04>;
			clocks = <0x02 0x41 0x02 0x93 0x02 0x8a>;
			clock-names = "ahb\0mod\0ram";
			resets = <0x02 0x08>;
			phandle = <0x0a>;

			ports {
				#address-cells = <0x01>;
				#size-cells = <0x00>;

				port@1 {
					#address-cells = <0x01>;
					#size-cells = <0x00>;
					reg = <0x01>;

					endpoint@0 {
						reg = <0x00>;
						remote-endpoint = <0x3a>;
						phandle = <0x41>;
					};

					endpoint@1 {
						reg = <0x01>;
						remote-endpoint = <0x3b>;
						phandle = <0x3d>;
					};
				};
			};
		};

		display-backend@1e40000 {
			compatible = "allwinner,sun7i-a20-display-backend";
			reg = <0x1e40000 0x10000>;
			interrupts = <0x00 0x30 0x04>;
			clocks = <0x02 0x3f 0x02 0x91 0x02 0x8d>;
			clock-names = "ahb\0mod\0ram";
			resets = <0x02 0x06>;

			ports {
				#address-cells = <0x01>;
				#size-cells = <0x00>;

				port@0 {
					#address-cells = <0x01>;
					#size-cells = <0x00>;
					reg = <0x00>;

					endpoint@0 {
						reg = <0x00>;
						remote-endpoint = <0x3c>;
						phandle = <0x39>;
					};

					endpoint@1 {
						reg = <0x01>;
						remote-endpoint = <0x3d>;
						phandle = <0x3b>;
					};
				};

				port@1 {
					#address-cells = <0x01>;
					#size-cells = <0x00>;
					reg = <0x01>;

					endpoint@0 {
						reg = <0x00>;
						remote-endpoint = <0x3e>;
						phandle = <0x0f>;
					};

					endpoint@1 {
						reg = <0x01>;
						remote-endpoint = <0x3f>;
						phandle = <0x13>;
					};
				};
			};
		};

		display-backend@1e60000 {
			compatible = "allwinner,sun7i-a20-display-backend";
			reg = <0x1e60000 0x10000>;
			interrupts = <0x00 0x2f 0x04>;
			clocks = <0x02 0x3e 0x02 0x90 0x02 0x8c>;
			clock-names = "ahb\0mod\0ram";
			resets = <0x02 0x05>;
			status = "okay";

			ports {
				#address-cells = <0x01>;
				#size-cells = <0x00>;

				port@0 {
					#address-cells = <0x01>;
					#size-cells = <0x00>;
					reg = <0x00>;

					endpoint@0 {
						reg = <0x00>;
						remote-endpoint = <0x40>;
						phandle = <0x38>;
					};

					endpoint@1 {
						reg = <0x01>;
						remote-endpoint = <0x41>;
						phandle = <0x3a>;
					};
				};

				port@1 {
					#address-cells = <0x01>;
					#size-cells = <0x00>;
					reg = <0x01>;

					endpoint@0 {
						reg = <0x00>;
						remote-endpoint = <0x42>;
						phandle = <0x0e>;
					};

					endpoint@1 {
						reg = <0x01>;
						remote-endpoint = <0x43>;
						phandle = <0x12>;
					};
				};
			};
		};
	};

	ahci-5v {
		compatible = "regulator-fixed";
		regulator-name = "ahci-5v";
		regulator-min-microvolt = <0x4c4b40>;
		regulator-max-microvolt = <0x4c4b40>;
		regulator-boot-on;
		enable-active-high;
		gpio = <0x18 0x01 0x08 0x00>;
		status = "okay";
		phandle = <0x22>;
	};

	usb0-vbus {
		compatible = "regulator-fixed";
		regulator-name = "usb0-vbus";
		regulator-min-microvolt = <0x4c4b40>;
		regulator-max-microvolt = <0x4c4b40>;
		enable-active-high;
		gpio = <0x18 0x01 0x09 0x00>;
		status = "disabled";
	};

	usb1-vbus {
		compatible = "regulator-fixed";
		regulator-name = "usb1-vbus";
		regulator-min-microvolt = <0x4c4b40>;
		regulator-max-microvolt = <0x4c4b40>;
		regulator-boot-on;
		enable-active-high;
		gpio = <0x18 0x07 0x06 0x00>;
		status = "okay";
	};

	usb2-vbus {
		compatible = "regulator-fixed";
		regulator-name = "usb2-vbus";
		regulator-min-microvolt = <0x4c4b40>;
		regulator-max-microvolt = <0x4c4b40>;
		regulator-boot-on;
		enable-active-high;
		gpio = <0x18 0x07 0x03 0x00>;
		status = "okay";
	};

	vcc3v0 {
		compatible = "regulator-fixed";
		regulator-name = "vcc3v0";
		regulator-min-microvolt = <0x2dc6c0>;
		regulator-max-microvolt = <0x2dc6c0>;
		phandle = <0x2c>;
	};

	vcc3v3 {
		compatible = "regulator-fixed";
		regulator-name = "vcc3v3";
		regulator-min-microvolt = <0x325aa0>;
		regulator-max-microvolt = <0x325aa0>;
		phandle = <0x17>;
	};

	vcc5v0 {
		compatible = "regulator-fixed";
		regulator-name = "vcc5v0";
		regulator-min-microvolt = <0x4c4b40>;
		regulator-max-microvolt = <0x4c4b40>;
	};

	hdmi-connector {
		compatible = "hdmi-connector";
		type = [61 00];

		port {

			endpoint {
				remote-endpoint = <0x44>;
				phandle = <0x21>;
			};
		};
	};

	backlight {
		compatible = "pwm-backlight";
		pwms = <0x45 0x00 0xc350 0x00>;
		brightness-levels = <0x00 0x0a 0x14 0x1e 0x28 0x32 0x3c 0x46 0x50 0x5a 0x64>;
		default-brightness-level = <0x05>;
		enable-gpios = <0x18 0x07 0x07 0x00>;
		phandle = <0x46>;
	};

	panel {
		compatible = "xiegu,gsoc-7inch\0simple-panel";
		power-supply = <0x17>;
		enable-gpios = <0x18 0x07 0x08 0x00>;
		backlight = <0x46>;

		port {

			endpoint {
				remote-endpoint = <0x47>;
				phandle = <0x11>;
			};
		};
	};

	gmac-3v3 {
		compatible = "regulator-fixed";
		regulator-name = "gmac-3v3";
		regulator-min-microvolt = <0x325aa0>;
		regulator-max-microvolt = <0x325aa0>;
		startup-delay-us = <0x186a0>;
		enable-active-high;
	};

	global-v33 {
		compatible = "regulator-fixed";
		regulator-name = "global-3v3";
		regulator-min-microvolt = <0x325aa0>;
		regulator-max-microvolt = <0x325aa0>;
		startup-delay-us = <0x186a0>;
		enable-active-high;
		phandle = <0x34>;
	};

	global-v50 {
		compatible = "regulator-fixed";
		regulator-name = "global-5v0";
		regulator-min-microvolt = <0x4c4b40>;
		regulator-max-microvolt = <0x4c4b40>;
		startup-delay-us = <0x186a0>;
		enable-active-high;
		phandle = <0x1e>;
	};

	mmc2_pwrseq {
		compatible = "mmc-pwrseq-emmc";
		reset-gpios = <0x18 0x02 0x18 0x01>;
		phandle = <0x1a>;
	};

	rtl_pwrseq {
		compatible = "mmc-pwrseq-simple";
		reset-gpios = <0x18 0x07 0x09 0x01>;
	};

	ref26M-tcxo {
		compatible = "fixed-clock";
		#clock-cells = <0x00>;
		clock-frequency = <0x18cba80>;
		phandle = <0x35>;
	};

	i2s-clk {
		compatible = "fixed-clock";
		#clock-cells = <0x00>;
		clock-frequency = <0x1770000>;
		phandle = <0x4a>;
	};

	sound {
		compatible = "simple-audio-card";
		simple-audio-card,name = "GSOC-Sound-Card";
		simple-audio-card,format = "i2s";
		simple-audio-card,bitclock-master = <0x48>;
		simple-audio-card,frame-master = <0x48>;
		simple-audio-card,mclk-fs = <0x80>;
		simple-audio-card,widgets = "Line\0Line In\0Line\0Line Out";
		simple-audio-card,routing = "Line Out\0AOUTA+\0Line Out\0AOUTA-\0Line Out\0AOUTB+\0Line Out\0AOUTB-\0AINA\0Line In\0AINB\0Line In";

		simple-audio-card,cpu {
			sound-dai = <0x49 0x00>;
			clocks = <0x4a>;
		};

		simple-audio-card,codec {
			sound-dai = <0x4b>;
			clocks = <0x4a>;
			system-clock-direction = "out";
			phandle = <0x48>;
		};
	};
};
